# MGM260PD22VNA register map
Vendor: Silicon Labs; Series: EFR32; File version: 2
Registers are 32-bit, read-write, reset 0x0 unless marked. A register's access mark holds for its fields unless they carry their own. Offsets are from the block's base; [hi:lo] are bit positions; {n}, {i} and the like mark numbered series.

## SMU_NS — SMU_NS Registers
Base 0x54008000
Same registers: SMU_S 0x44008000
0x00 IPVERSION ro reset 0x7
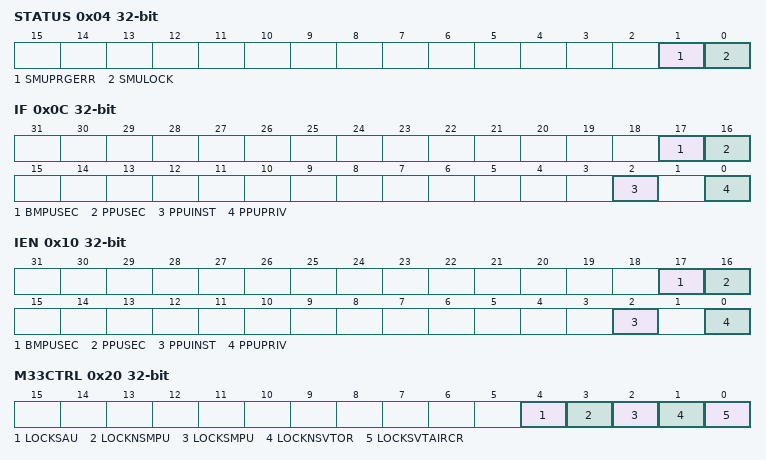
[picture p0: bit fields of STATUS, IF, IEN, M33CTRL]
0x04 STATUS ro
  [1] SMUPRGERR — SMU Programming Error
  [0] SMULOCK
    0=UNLOCKED; 1=LOCKED
0x08 LOCK wo
  [23:0] SMULOCKKEY
    0xACCE55=UNLOCK (Unlocks Registers)
0x0C IF
  [17] BMPUSEC — BMPU Security Interrupt Flag
  [16] PPUSEC — PPU Security Interrupt Flag
  [2] PPUINST — PPU Instruction Interrupt Flag
  [0] PPUPRIV — PPU Privilege Interrupt Flag
0x10 IEN
  [17] BMPUSEC — BMPU Security Interrupt Enable
  [16] PPUSEC — PPU Security Interrupt Enable
  [2] PPUINST — PPU Instruction Interrupt Enable
  [0] PPUPRIV — PPU Privilege Interrupt Enable
0x20 M33CTRL — Holds the M33 control settings
  [4] LOCKSAU — New BitField
  [3] LOCKNSMPU — New BitField
  [2] LOCKSMPU — New BitField
  [1] LOCKNSVTOR — New BitField
  [0] LOCKSVTAIRCR — New BitField
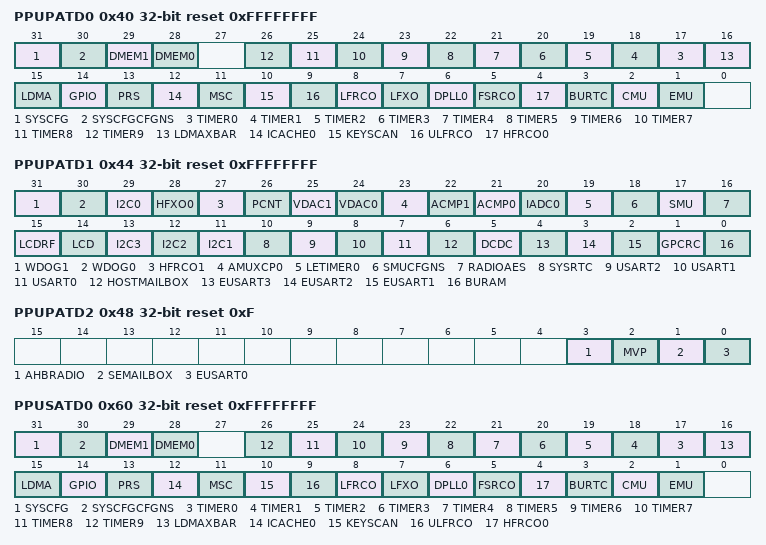
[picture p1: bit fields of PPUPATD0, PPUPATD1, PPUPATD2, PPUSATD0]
0x40 PPUPATD0 reset 0xFFFFFFFF — Set peripheral bits to 1 to mark as privileged access only
  [31] SYSCFG — SYSCFG Privileged Access
  [30] SYSCFGCFGNS — SYSCFGCFGNS Privileged Access
  [29] DMEM1 — DMEM1 Privileged Access
  [28] DMEM0 — DMEM0 Privileged Access
  [n+17] TIMER{n} (n=0..9) — TIMER{n} Privileged Access
  [16] LDMAXBAR — LDMAXBAR Privileged Access
  [15] LDMA — LDMA Privileged Access
  [14] GPIO — GPIO Privileged Access
  [13] PRS — PRS Privileged Access
  [12] ICACHE0 — ICACHE0 Privileged Access
  [11] MSC — MSC Privileged Access
  [10] KEYSCAN — KEYSCAN Privileged Access
  [9] ULFRCO — ULFRCO Privileged Access
  [8] LFRCO — LFRCO Privileged Access
  [7] LFXO — LFXO Privileged Access
  [6] DPLL0 — DPLL0 Privileged Access
  [5] FSRCO — FSRCO Privileged Access
  [4] HFRCO0 — HFRCO0 Privileged Access
  [3] BURTC — BURTC Privileged Access
  [2] CMU — CMU Privileged Access
  [1] EMU — EMU Privileged Access
0x44 PPUPATD1 reset 0xFFFFFFFF — Set peripheral bits to 1 to mark as privileged access only
  [31] WDOG1 — WDOG1 Privileged Access
  [30] WDOG0 — WDOG0 Privileged Access
  [29] I2C0 — I2C0 Privileged Access
  [28] HFXO0 — HFXO0 Privileged Access
  [27] HFRCO1 — HFRCO1 Privileged Access
  [26] PCNT — PCNT Privileged Access
  [25] VDAC1 — VDAC1 Privileged Access
  [24] VDAC0 — VDAC0 Privileged Access
  [23] AMUXCP0 — AMUXCP0 Privileged Access
  [22] ACMP1 — ACMP1 Privileged Access
  [21] ACMP0 — ACMP0 Privileged Access
  [20] IADC0 — IADC0 Privileged Access
  [19] LETIMER0 — LETIMER0 Privileged Access
  [18] SMUCFGNS — SMUCFGNS Privileged Access
  [17] SMU — SMU Privileged Access
  [16] RADIOAES — RADIOAES Privileged Access
  [15] LCDRF — LCDRF Privileged Access
  [14] LCD — LCD Privileged Access
  [13] I2C3 — I2C3 Privileged Access
  [12] I2C2 — I2C2 Privileged Access
  [11] I2C1 — I2C1 Privileged Access
  [10] SYSRTC — SYSRTC Privileged Access
  [9] USART2 — USART2 Privileged Access
  [8] USART1 — USART1 Privileged Access
  [7] USART0 — USART0 Privileged Access
  [6] HOSTMAILBOX — HOSTMAILBOX Privileged Access
  [5] DCDC — DCDC Privileged Access
  [4] EUSART3 — EUSART3 Privileged Access
  [3] EUSART2 — EUSART2 Privileged Access
  [2] EUSART1 — EUSART1 Privileged Access
  [1] GPCRC — GPCRC Privileged Access
  [0] BURAM — BURAM Privileged Access
0x48 PPUPATD2 reset 0xF — Set peripheral bits to 1 to mark as privileged access only
  [3] AHBRADIO — AHBRADIO Privileged Access
  [2] MVP — MVP Privileged Access
  [1] SEMAILBOX — SEMAILBOX Privileged Access
  [0] EUSART0 — EUSART0 Privileged Access
0x60 PPUSATD0 reset 0xFFFFFFFF — Set peripheral bits to 1 to mark as secure access only
  [31] SYSCFG — SYSCFG Secure Access
  [30] SYSCFGCFGNS — SYSCFGCFGNS Secure Access
  [29] DMEM1 — DMEM1 Secure Access
  [28] DMEM0 — DMEM0 Secure Access
  [n+17] TIMER{n} (n=0..9) — TIMER{n} Secure Access
  [16] LDMAXBAR — LDMAXBAR Secure Access
  [15] LDMA — LDMA Secure Access
  [14] GPIO — GPIO Secure Access
  [13] PRS — PRS Secure Access
  [12] ICACHE0 — ICACHE0 Secure Access
  [11] MSC — MSC Secure Access
  [10] KEYSCAN — KEYSCAN Secure Access
  [9] ULFRCO — ULFRCO Secure Access
  [8] LFRCO — LFRCO Secure Access
  [7] LFXO — LFXO Secure Access
  [6] DPLL0 — DPLL0 Secure Access
  [5] FSRCO — FSRCO Secure Access
  [4] HFRCO0 — HFRCO0 Secure Access
  [3] BURTC — BURTC Secure Access
  [2] CMU — CMU Secure Access
  [1] EMU — EMU Secure Access
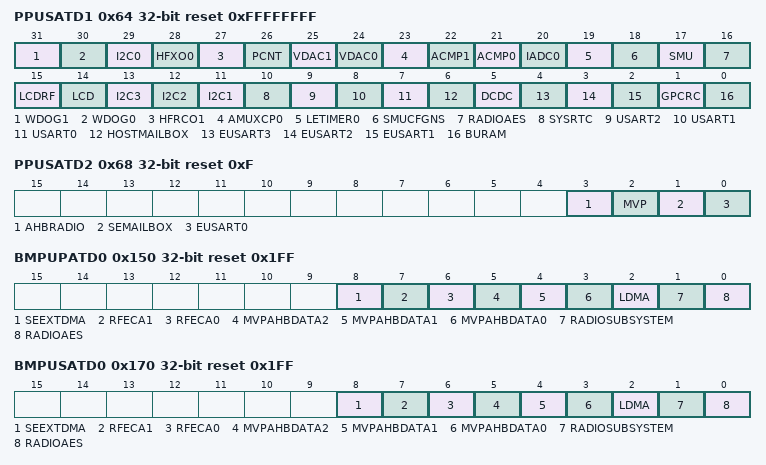
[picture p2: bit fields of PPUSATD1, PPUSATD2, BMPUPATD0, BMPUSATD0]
0x64 PPUSATD1 reset 0xFFFFFFFF — Set peripheral bits to 1 to mark as secure access only
  [31] WDOG1 — WDOG1 Secure Access
  [30] WDOG0 — WDOG0 Secure Access
  [29] I2C0 — I2C0 Secure Access
  [28] HFXO0 — HFXO0 Secure Access
  [27] HFRCO1 — HFRCO1 Secure Access
  [26] PCNT — PCNT Secure Access
  [25] VDAC1 — VDAC1 Secure Access
  [24] VDAC0 — VDAC0 Secure Access
  [23] AMUXCP0 — AMUXCP0 Secure Access
  [22] ACMP1 — ACMP1 Secure Access
  [21] ACMP0 — ACMP0 Secure Access
  [20] IADC0 — IADC0 Secure Access
  [19] LETIMER0 — LETIMER0 Secure Access
  [18] SMUCFGNS — SMUCFGNS Secure Access
  [17] SMU — SMU Secure Access
  [16] RADIOAES — RADIOAES Secure Access
  [15] LCDRF — LCDRF Secure Access
  [14] LCD — LCD Secure Access
  [13] I2C3 — I2C3 Secure Access
  [12] I2C2 — I2C2 Secure Access
  [11] I2C1 — I2C1 Secure Access
  [10] SYSRTC — SYSRTC Secure Access
  [9] USART2 — USART2 Secure Access
  [8] USART1 — USART1 Secure Access
  [7] USART0 — USART0 Secure Access
  [6] HOSTMAILBOX — HOSTMAILBOX Secure Access
  [5] DCDC — DCDC Secure Access
  [4] EUSART3 — EUSART3 Secure Access
  [3] EUSART2 — EUSART2 Secure Access
  [2] EUSART1 — EUSART1 Secure Access
  [1] GPCRC — GPCRC Secure Access
  [0] BURAM — BURAM Secure Access
0x68 PPUSATD2 reset 0xF — Set peripheral bits to 1 to mark as secure access only
  [3] AHBRADIO — AHBRADIO Secure Access
  [2] MVP — MVP Secure Access
  [1] SEMAILBOX — SEMAILBOX Secure Access
  [0] EUSART0 — EUSART0 Secure Access
0x140 PPUFS ro
  [7:0] PPUFSPERIPHID — Peripheral ID
0x150 BMPUPATD0 reset 0x1FF — Set master bits to 1 to mark as a privileged master
  [8] SEEXTDMA — SEEXTDMA Privileged Mode
  [7] RFECA1 — RFECA1 Privileged Mode
  [6] RFECA0 — RFECA0 Privileged Mode
  [5] MVPAHBDATA2 — MVPAHBDATA2 Privileged Mode
  [4] MVPAHBDATA1 — MVPAHBDATA1 Privileged Mode
  [3] MVPAHBDATA0 — MVPAHBDATA0 Privileged Mode
  [2] LDMA — LDMA Privileged Mode
  [1] RADIOSUBSYSTEM — RADIOSUBSYSTEM Privileged Mode
  [0] RADIOAES — RADIOAES Privileged Mode
0x170 BMPUSATD0 reset 0x1FF — Set master bits to 1 to mark as a secure master
  [8] SEEXTDMA — SEEXTDMA Secure Mode
  [7] RFECA1 — RFECA1 Secure Mode
  [6] RFECA0 — RFECA0 Secure Mode
  [5] MVPAHBDATA2 — MVPAHBDATA2 Secure Mode
  [4] MVPAHBDATA1 — MVPAHBDATA1 Secure Mode
  [3] MVPAHBDATA0 — MVPAHBDATA0 Secure Mode
  [2] LDMA — LDMA Secure Mode
  [1] RADIOSUBSYSTEM — RADIOSUBSYSTEM Secure Mode
  [0] RADIOAES — RADIOAES Secure Mode
0x250 BMPUFS ro
  [7:0] BMPUFSMASTERID — Bus Manager ID
0x254 BMPUFSADDR ro
  [31:0] BMPUFSADDR — Fault Address
0x260 ESAURTYPES0
  [12] ESAUR3NS — Region 3 Non-Secure
0x264 ESAURTYPES1
  [12] ESAUR11NS — Region 11 Non-Secure
0x270 ESAUMRB01 reset 0xA000000
  [27:12] ESAUMRB01 — Moveable Region Boundary
0x274 ESAUMRB12 reset 0xC000000
  [27:12] ESAUMRB12 — Moveable Region Boundary
0x280 ESAUMRB45 reset 0x2000000
  [27:12] ESAUMRB45 — Moveable Region Boundary
0x284 ESAUMRB56 reset 0x4000000
  [27:12] ESAUMRB56 — Moveable Region Boundary
